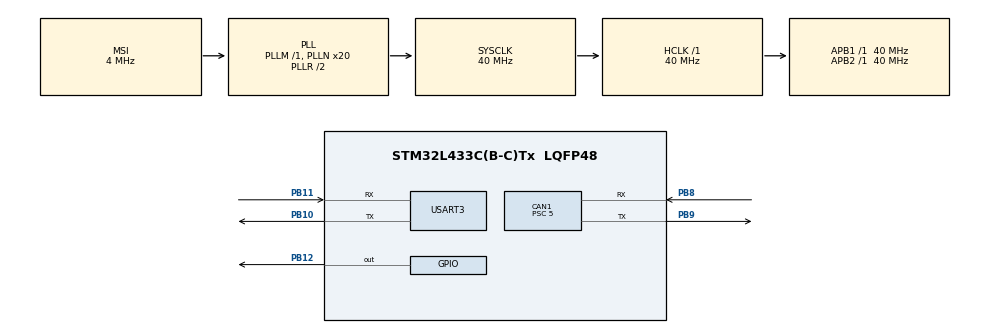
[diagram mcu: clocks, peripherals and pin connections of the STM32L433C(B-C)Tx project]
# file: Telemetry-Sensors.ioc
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CAN1.BS1=CAN_BS1_13TQ
CAN1.BS2=CAN_BS2_2TQ
CAN1.CalculateBaudRate=500000
CAN1.CalculateTimeBit=2000
CAN1.CalculateTimeQuantum=125.0
CAN1.Prescaler=5
FREERTOS.Tasks01=defaultTask,24,128,StartDefaultTask,Default,NULL,Dynamic,NULL,NULL;msgTask,8,128,StartMsgTask,Default,NULL,Dynamic,NULL,NULL
Mcu.Family=STM32L4
Mcu.Name=STM32L433C(B-C)Tx
Mcu.Package=LQFP48
NVIC.PriorityGroup=NVIC_PRIORITYGROUP_4
NVIC.TIM6_DAC_IRQn=true\:15\:0\:false\:false\:true\:false\:false\:true\:true
NVIC.TimeBase=TIM6_DAC_IRQn
NVIC.TimeBaseIP=TIM6
PA13\ (JTMS-SWDIO).Mode=Trace_Asynchronous_SW
PA13\ (JTMS-SWDIO).Signal=SYS_JTMS-SWDIO
PA14\ (JTCK-SWCLK).Mode=Trace_Asynchronous_SW
PA14\ (JTCK-SWCLK).Signal=SYS_JTCK-SWCLK
PB10.Mode=Asynchronous
PB10.Signal=USART3_TX
PB11.Mode=Asynchronous
PB11.Signal=USART3_RX
PB12.Signal=GPIO_Output
PB3\ (JTDO-TRACESWO).Mode=Trace_Asynchronous_SW
PB3\ (JTDO-TRACESWO).Signal=SYS_JTDO-SWO
PB8.Mode=CAN_Activate
PB8.Signal=CAN1_RX
PB9.Mode=CAN_Activate
PB9.Signal=CAN1_TX
ProjectManager.HeapSize=0x200
ProjectManager.StackSize=0x400
ProjectManager.TargetToolchain=Makefile
RCC.ADCFreq_Value=16000000
RCC.AHBFreq_Value=40000000
RCC.APB1Freq_Value=40000000
RCC.APB1TimFreq_Value=40000000
RCC.APB2Freq_Value=40000000
RCC.APB2TimFreq_Value=40000000
RCC.CortexFreq_Value=40000000
RCC.HCLKFreq_Value=40000000
RCC.HSE_VALUE=8000000
RCC.HSI48_VALUE=48000000
RCC.HSI_VALUE=16000000
RCC.LSE_VALUE=32768
RCC.MSI_VALUE=4000000
RCC.PLLN=20
RCC.SYSCLKFreq_VALUE=40000000
RCC.SYSCLKSource=RCC_SYSCLKSOURCE_PLLCLK
RCC.USBFreq_Value=16000000
RCC.VCOOutputFreq_Value=80000000
USART3.VirtualMode-Asynchronous=VM_ASYNC
VP_FREERTOS_VS_CMSIS_V2.Mode=CMSIS_V2
VP_SYS_VS_tim6.Mode=TIM6
board=custom

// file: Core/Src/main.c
/* USER CODE BEGIN Header */
/**
  ******************************************************************************
  * @file           : main.c
  * @brief          : Main program body
  ******************************************************************************
  * @attention
  *
  * Copyright (c) 2026 STMicroelectronics.
  * All rights reserved.
  *
  * This software is licensed under terms that can be found in the LICENSE file
  * in the root directory of this software component.
  * If no LICENSE file comes with this software, it is provided AS-IS.
  *
  ******************************************************************************
  */
/* USER CODE END Header */
#include "main.h"
#include "cmsis_os.h"

/* USER CODE BEGIN Includes */
#include "user.hpp"
/* USER CODE END Includes */

CAN_HandleTypeDef hcan1;

UART_HandleTypeDef huart3;

/* Definitions for defaultTask */
osThreadId_t defaultTaskHandle;
const osThreadAttr_t defaultTask_attributes = {
  .name = "defaultTask",
  .stack_size = 128 * 4,
  .priority = (osPriority_t) osPriorityNormal,
};
/* Definitions for msgTask */
osThreadId_t msgTaskHandle;
const osThreadAttr_t msgTask_attributes = {
  .name = "msgTask",
  .stack_size = 128 * 4,
  .priority = (osPriority_t) osPriorityLow,
};

void SystemClock_Config(void);
static void MX_GPIO_Init(void);
static void MX_CAN1_Init(void);
static void MX_USART3_UART_Init(void);
void StartDefaultTask(void *argument);
void StartMsgTask(void *argument);

int main(void)
{

  /* MCU Configuration--------------------------------------------------------*/

  /* Reset of all peripherals, Initializes the Flash interface and the Systick. */
  HAL_Init();

  /* Configure the system clock */
  SystemClock_Config();

  /* Initialize all configured peripherals */
  MX_GPIO_Init();
  MX_CAN1_Init();
  MX_USART3_UART_Init();

  /* Init scheduler */
  osKernelInitialize();

  /* Create the thread(s) */
  /* creation of defaultTask */
  defaultTaskHandle = osThreadNew(StartDefaultTask, NULL, &defaultTask_attributes);

  /* creation of msgTask */
  msgTaskHandle = osThreadNew(StartMsgTask, NULL, &msgTask_attributes);

  /* Start scheduler */
  osKernelStart();

  /* We should never get here as control is now taken by the scheduler */

  /* Infinite loop */
  while (1)
  {

  }
}

void SystemClock_Config(void)
{
  RCC_OscInitTypeDef RCC_OscInitStruct = {0};
  RCC_ClkInitTypeDef RCC_ClkInitStruct = {0};

  /** Configure the main internal regulator output voltage
  */
  if (HAL_PWREx_ControlVoltageScaling(PWR_REGULATOR_VOLTAGE_SCALE1) != HAL_OK)
  {
    Error_Handler();
  }

  /** Initializes the RCC Oscillators according to the specified parameters
  * in the RCC_OscInitTypeDef structure.
  */
  RCC_OscInitStruct.OscillatorType = RCC_OSCILLATORTYPE_MSI;
  RCC_OscInitStruct.MSIState = RCC_MSI_ON;
  RCC_OscInitStruct.MSICalibrationValue = 0;
  RCC_OscInitStruct.MSIClockRange = RCC_MSIRANGE_6;
  RCC_OscInitStruct.PLL.PLLState = RCC_PLL_ON;
  RCC_OscInitStruct.PLL.PLLSource = RCC_PLLSOURCE_MSI;
  RCC_OscInitStruct.PLL.PLLM = 1;
  RCC_OscInitStruct.PLL.PLLN = 20;
  RCC_OscInitStruct.PLL.PLLP = RCC_PLLP_DIV7;
  RCC_OscInitStruct.PLL.PLLQ = RCC_PLLQ_DIV2;
  RCC_OscInitStruct.PLL.PLLR = RCC_PLLR_DIV2;
  if (HAL_RCC_OscConfig(&RCC_OscInitStruct) != HAL_OK)
  {
    Error_Handler();
  }

  /** Initializes the CPU, AHB and APB buses clocks
  */
  RCC_ClkInitStruct.ClockType = RCC_CLOCKTYPE_HCLK|RCC_CLOCKTYPE_SYSCLK
                              |RCC_CLOCKTYPE_PCLK1|RCC_CLOCKTYPE_PCLK2;
  RCC_ClkInitStruct.SYSCLKSource = RCC_SYSCLKSOURCE_PLLCLK;
  RCC_ClkInitStruct.AHBCLKDivider = RCC_SYSCLK_DIV1;
  RCC_ClkInitStruct.APB1CLKDivider = RCC_HCLK_DIV1;
  RCC_ClkInitStruct.APB2CLKDivider = RCC_HCLK_DIV1;

  if (HAL_RCC_ClockConfig(&RCC_ClkInitStruct, FLASH_LATENCY_2) != HAL_OK)
  {
    Error_Handler();
  }
}

static void MX_CAN1_Init(void)
{

  hcan1.Instance = CAN1;
  hcan1.Init.Prescaler = 5;
  hcan1.Init.Mode = CAN_MODE_NORMAL;
  hcan1.Init.SyncJumpWidth = CAN_SJW_1TQ;
  hcan1.Init.TimeSeg1 = CAN_BS1_13TQ;
  hcan1.Init.TimeSeg2 = CAN_BS2_2TQ;
  hcan1.Init.TimeTriggeredMode = DISABLE;
  hcan1.Init.AutoBusOff = DISABLE;
  hcan1.Init.AutoWakeUp = DISABLE;
  hcan1.Init.AutoRetransmission = DISABLE;
  hcan1.Init.ReceiveFifoLocked = DISABLE;
  hcan1.Init.TransmitFifoPriority = DISABLE;
  if (HAL_CAN_Init(&hcan1) != HAL_OK)
  {
    Error_Handler();
  }

}

static void MX_USART3_UART_Init(void)
{

  huart3.Instance = USART3;
  huart3.Init.BaudRate = 115200;
  huart3.Init.WordLength = UART_WORDLENGTH_8B;
  huart3.Init.StopBits = UART_STOPBITS_1;
  huart3.Init.Parity = UART_PARITY_NONE;
  huart3.Init.Mode = UART_MODE_TX_RX;
  huart3.Init.HwFlowCtl = UART_HWCONTROL_NONE;
  huart3.Init.OverSampling = UART_OVERSAMPLING_16;
  huart3.Init.OneBitSampling = UART_ONE_BIT_SAMPLE_DISABLE;
  huart3.AdvancedInit.AdvFeatureInit = UART_ADVFEATURE_NO_INIT;
  if (HAL_UART_Init(&huart3) != HAL_OK)
  {
    Error_Handler();
  }

}

static void MX_GPIO_Init(void)
{
  GPIO_InitTypeDef GPIO_InitStruct = {0};

  /* GPIO Ports Clock Enable */
  __HAL_RCC_GPIOB_CLK_ENABLE();
  __HAL_RCC_GPIOA_CLK_ENABLE();

  /*Configure GPIO pin Output Level */
  HAL_GPIO_WritePin(GPIOB, GPIO_PIN_12, GPIO_PIN_RESET);

  /*Configure GPIO pin : PB12 */
  GPIO_InitStruct.Pin = GPIO_PIN_12;
  GPIO_InitStruct.Mode = GPIO_MODE_OUTPUT_PP;
  GPIO_InitStruct.Pull = GPIO_NOPULL;
  GPIO_InitStruct.Speed = GPIO_SPEED_FREQ_LOW;
  HAL_GPIO_Init(GPIOB, &GPIO_InitStruct);

}

void StartDefaultTask(void *argument)
{
  /* USER CODE BEGIN 5 */
  /* Infinite loop */
  startDefaultTask_user(argument);
  /* USER CODE END 5 */
}

void StartMsgTask(void *argument)
{
  /* USER CODE BEGIN StartMsgTask */
  /* Infinite loop */
  startMsgTask_user(argument);
  /* USER CODE END StartMsgTask */
}

void HAL_TIM_PeriodElapsedCallback(TIM_HandleTypeDef *htim)
{
  if (htim->Instance == TIM6)
  {
    HAL_IncTick();
  }
}

void Error_Handler(void)
{
  __disable_irq();
  while (1)
  {
  }
}
